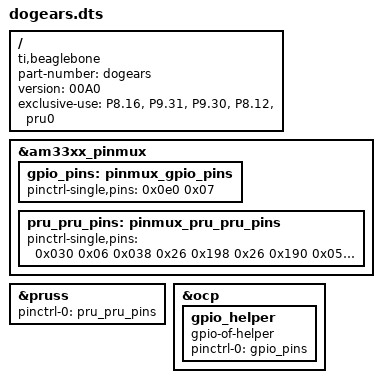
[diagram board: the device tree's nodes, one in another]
/dts-v1/;
/plugin/;

/ {
   compatible = "ti,beaglebone", "ti,beaglebone-black";

   part-number = "dogears";
   version = "00A0";

   /* This overlay uses the following resources */
   exclusive-use =
         "P8.16", "P9.31", "P9.30", "P8.12", "pru0";

   fragment@0 {
      target = <&am33xx_pinmux>;
      __overlay__ {

         gpio_pins: pinmux_gpio_pins {         // The GPIO pins
            pinctrl-single,pins = <
               0x0e0 0x07  // GCTRL0 P9_11 MODE7 | OUTPUT | GPIO pull-down
            >;
         };

         pru_pru_pins: pinmux_pru_pru_pins {   // The PRU pin modes
            pinctrl-single,pins = <
               // First column is the offset identifying the pin, taken from this table: https://elinux.org/Ti_AM33XX_PRUSSv2#Beaglebone_PRU_connections_and_modes
               // Second column is the pin mode, calculated from Table 9-60 of https://www.ti.com/lit/ug/spruh73p/spruh73p.pdf#page=1512
               0x030 0x06  // /SYNC P8_12 pr1_pru0_pru_r30_14, MODE6 | OUTPUT | PRU
               0x038 0x26  // /DRDY P8_16 pr1_pru0_pru_r31_14, MODE6 | INPUT | PRU
               0x198 0x26  //  MISO P9_30 pr1_pru0_pru_r31_2, MODE6 | INPUT | PRU
               0x190 0x05  //  SCLK P9_31 pr1_pru0_pru_r31_0, MODE6 | OUTPUT | PRU
               0x0ac 0x1e  //  DBUG P8_44 pr1_pru1_pru_r31_3, MODE6 | OUTPUT | PRU
            >;
         };
      };
   };

   fragment@1 {         // Enable the PRUSS
      target = <&pruss>;
      __overlay__ {
         status = "okay";
         pinctrl-names = "default";
         pinctrl-0 = <&pru_pru_pins>;
      };
   };

   fragment@2 {         // Enable the GPIOs
      target = <&ocp>;
      __overlay__ {
         gpio_helper {
            compatible = "gpio-of-helper";
            status = "okay";
            pinctrl-names = "default";
            pinctrl-0 = <&gpio_pins>;
         };
      };
   };
};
